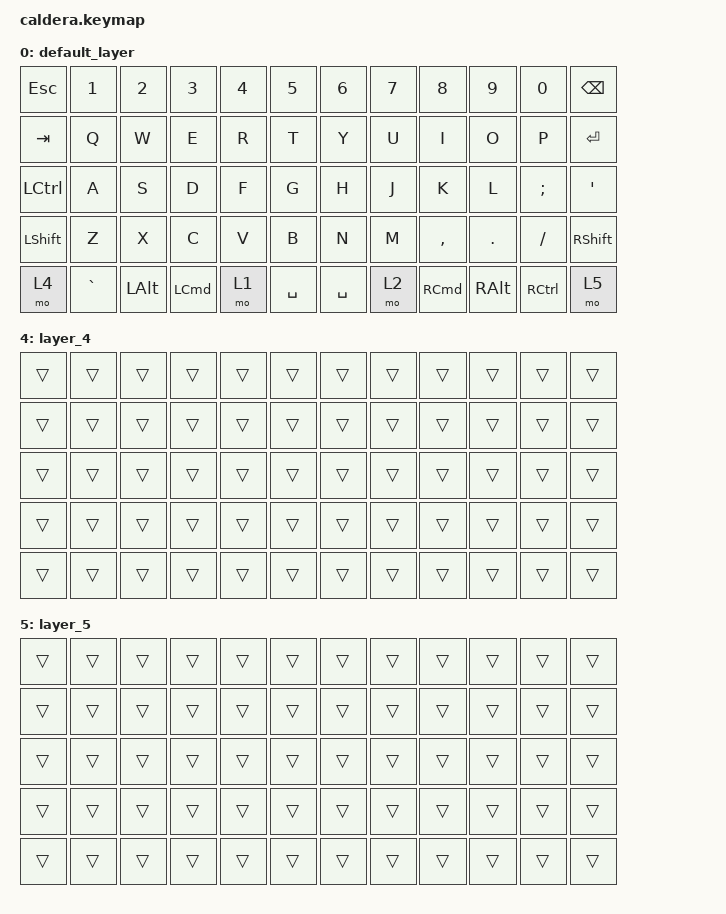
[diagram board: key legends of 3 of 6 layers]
#include <behaviors.dtsi>
#include <dt-bindings/zmk/bt.h>
#include <dt-bindings/zmk/keys.h>

/ {
    keymap {
        compatible = "zmk,keymap";

        default_layer {
            bindings = <
&kp ESCAPE        &kp N1     &kp N2        &kp N3            &kp N4  &kp N5       &kp N6     &kp N7  &kp N8             &kp N9         &kp N0             &kp BSPC
&kp TAB           &kp Q      &kp W         &kp E             &kp R   &kp T        &kp Y      &kp U   &kp I              &kp O          &kp P              &kp ENTER
&kp LEFT_CONTROL  &kp A      &kp S         &kp D             &kp F   &kp G        &kp H      &kp J   &kp K              &kp L          &kp SEMI           &kp SINGLE_QUOTE
&kp LSHFT         &kp Z      &kp X         &kp C             &kp V   &kp B        &kp N      &kp M   &kp COMMA          &kp DOT        &kp FSLH           &kp RIGHT_SHIFT
&mo 4             &kp GRAVE  &kp LEFT_ALT  &kp LEFT_COMMAND  &mo 1   &kp SPACE    &kp SPACE  &mo 2   &kp RIGHT_COMMAND  &kp RIGHT_ALT  &kp RIGHT_CONTROL  &mo 5
            >;
        };

        lower_layer {
            bindings = <
&trans  &kp F1            &kp F2             &kp F3     &kp F4    &kp F5    &kp F6             &kp F7    &kp F8        &kp F9     &kp F10  &kp DELETE
&trans  &kp GRAVE         &kp EQUAL          &kp MINUS  &trans    &trans    &kp C_VOLUME_UP    &trans    &kp UP_ARROW  &kp F11    &kp F12  &trans
&trans  &kp LEFT_BRACKET  &kp RIGHT_BRACKET  &kp LPAR   &kp RPAR  &trans    &kp C_VOLUME_DOWN  &kp LEFT  &kp DOWN      &kp RIGHT  &trans   &kp PIPE
&trans  &trans            &trans             &trans     &trans    &trans    &trans             &trans    &trans        &trans     &trans   &trans
            >;
        };

        upper_layer {
            bindings = <
&trans  &trans           &trans     &trans    &trans          &trans             &trans             &trans             &trans        &trans     &trans  &trans
&trans  &kp GRAVE        &trans     &trans    &trans          &trans             &kp C_VOLUME_UP    &trans             &kp UP_ARROW  &trans     &trans  &trans
&trans  &kp EXCLAMATION  &trans     &kp LPAR  &kp RPAR        &trans             &kp C_VOLUME_DOWN  &kp LEFT           &kp DOWN      &kp RIGHT  &trans  &trans
&trans  &kp EQUAL        &kp MINUS  &kp PLUS  &kp LEFT_BRACE  &kp RIGHT_BRACE    &kp LEFT_BRACKET   &kp RIGHT_BRACKET  &trans        &trans     &trans  &trans
            >;
        };

        config_layer {
            bindings = <
&trans  &bt BT_SEL 0  &bt BT_SEL 1  &bt BT_SEL 2  &bt BT_SEL 3  &bt BT_SEL 4    &trans  &trans  &trans  &trans  &trans  &bt BT_CLR
&trans  &trans        &trans        &trans        &trans        &trans          &trans  &trans  &trans  &trans  &trans  &trans
&trans  &trans        &trans        &trans        &trans        &trans          &trans  &trans  &trans  &trans  &trans  &trans
&trans  &trans        &trans        &trans        &trans        &trans          &trans  &trans  &trans  &trans  &trans  &trans
            >;
        };

        layer_4 {
            bindings = <
&trans  &trans  &trans  &trans  &trans  &trans    &trans  &trans  &trans  &trans  &trans  &trans
&trans  &trans  &trans  &trans  &trans  &trans    &trans  &trans  &trans  &trans  &trans  &trans
&trans  &trans  &trans  &trans  &trans  &trans    &trans  &trans  &trans  &trans  &trans  &trans
&trans  &trans  &trans  &trans  &trans  &trans    &trans  &trans  &trans  &trans  &trans  &trans
&trans  &trans  &trans  &trans  &trans  &trans    &trans  &trans  &trans  &trans  &trans  &trans
            >;
        };

        layer_5 {
            bindings = <
&trans  &trans  &trans  &trans  &trans  &trans    &trans  &trans  &trans  &trans  &trans  &trans
&trans  &trans  &trans  &trans  &trans  &trans    &trans  &trans  &trans  &trans  &trans  &trans
&trans  &trans  &trans  &trans  &trans  &trans    &trans  &trans  &trans  &trans  &trans  &trans
&trans  &trans  &trans  &trans  &trans  &trans    &trans  &trans  &trans  &trans  &trans  &trans
&trans  &trans  &trans  &trans  &trans  &trans    &trans  &trans  &trans  &trans  &trans  &trans
            >;
        };
    };

    conditional_layers {
        compatible = "zmk,conditional-layers";

        Config {
            if-layers = <4 5>;
            then-layer = <3>;
        };
    };
};
